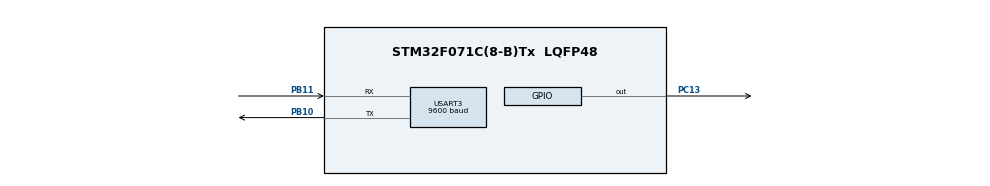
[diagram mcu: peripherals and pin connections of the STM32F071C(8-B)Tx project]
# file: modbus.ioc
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Mcu.Family=STM32F0
Mcu.Name=STM32F071C(8-B)Tx
Mcu.Package=LQFP48
NVIC.USART3_4_IRQn=true\:0\:0\:false\:false\:true\:true\:true\:true
PB10.Mode=Asynchronous
PB10.Signal=USART3_TX
PB11.Mode=Asynchronous
PB11.Signal=USART3_RX
PC13.Signal=GPIO_Output
ProjectManager.HeapSize=0x200
ProjectManager.StackSize=0x400
ProjectManager.TargetToolchain=STM32CubeIDE
USART3.BaudRate=9600
USART3.VirtualMode-Asynchronous=VM_ASYNC
board=custom

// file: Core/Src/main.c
/* USER CODE BEGIN Header */
/**
  ******************************************************************************
  * @file           : main.c
  * @brief          : Main program body
  ******************************************************************************
  * @attention
  *
  * Copyright (c) 2025 STMicroelectronics.
  * All rights reserved.
  *
  * This software is licensed under terms that can be found in the LICENSE file
  * in the root directory of this software component.
  * If no LICENSE file comes with this software, it is provided AS-IS.
  *
  ******************************************************************************
  */
/* USER CODE END Header */
#include "main.h"

/* USER CODE BEGIN Includes */
#include <string.h>
#include <stdio.h>
/* USER CODE END Includes */

UART_HandleTypeDef huart3;

/* USER CODE BEGIN PV */

uint16_t ModBus_CRC16(uint8_t *data, uint16_t length) {
  uint16_t crc = 0xFFFF;    // Initial value
  uint16_t i, j;

  for(i = 0; i < length; i++) {
      crc ^= data[i];       // XOR byte with CRC
      for(j = 0; j < 8; j++) {   // Process each bit
          if(crc & 0x0001) {     // If LSB is 1
              crc = (crc >> 1) ^ 0xA001;  // Shift right and XOR with polynomial
          } else {
              crc = crc >> 1;    // Just shift right
          }
      }
  }

  return crc;
}

/* USER CODE END PV */

void SystemClock_Config(void);
static void MX_GPIO_Init(void);
static void MX_USART3_UART_Init(void);

int main(void)
{

  /* MCU Configuration--------------------------------------------------------*/

  /* Reset of all peripherals, Initializes the Flash interface and the Systick. */
  HAL_Init();

  /* Configure the system clock */
  SystemClock_Config();

  /* Initialize all configured peripherals */
  MX_GPIO_Init();
  MX_USART3_UART_Init();
  /* USER CODE BEGIN 2 */
  uint8_t buffer[256];

  sprintf((char *)buffer, "Hello, World!\n");
  HAL_UART_Transmit(&huart3, buffer, strlen((char *)buffer), 100);
  int count = 0;
  uint8_t test = 0x00;
  uint8_t* arr_test = &test;
  uint8_t data;
  /* USER CODE END 2 */

  /* Infinite loop */
  while (1)
  {
    HAL_UART_Receive(&huart3, &data, sizeof(data),10);
    // if(data == 'a')
    {
      HAL_UART_Transmit(&huart3, "hi\r\n", 4, 100);

      HAL_Delay(1000);

      uint8_t response[] = {0x01, 0x03, 0x02, 0x11, *arr_test, 0xB4, 0x27};
      uint16_t crc = ModBus_CRC16(response, sizeof(response) - 2);
      uint8_t crc_low = crc & 0xFF;
      uint8_t crc_high = (crc >> 8) & 0xFF;
      response[sizeof(response) - 2] = crc_low;
      response[sizeof(response) - 1] = crc_high;

	    HAL_UART_Transmit(&huart3, &response, sizeof(response), 100);
	    HAL_Delay(1000);
      test++;
    }
	  HAL_Delay(1000);
  }
}

void SystemClock_Config(void)
{
  RCC_OscInitTypeDef RCC_OscInitStruct = {0};
  RCC_ClkInitTypeDef RCC_ClkInitStruct = {0};

  /** Initializes the RCC Oscillators according to the specified parameters
  * in the RCC_OscInitTypeDef structure.
  */
  RCC_OscInitStruct.OscillatorType = RCC_OSCILLATORTYPE_HSI;
  RCC_OscInitStruct.HSIState = RCC_HSI_ON;
  RCC_OscInitStruct.HSICalibrationValue = RCC_HSICALIBRATION_DEFAULT;
  RCC_OscInitStruct.PLL.PLLState = RCC_PLL_NONE;
  if (HAL_RCC_OscConfig(&RCC_OscInitStruct) != HAL_OK)
  {
    Error_Handler();
  }

  /** Initializes the CPU, AHB and APB buses clocks
  */
  RCC_ClkInitStruct.ClockType = RCC_CLOCKTYPE_HCLK|RCC_CLOCKTYPE_SYSCLK
                              |RCC_CLOCKTYPE_PCLK1;
  RCC_ClkInitStruct.SYSCLKSource = RCC_SYSCLKSOURCE_HSI;
  RCC_ClkInitStruct.AHBCLKDivider = RCC_SYSCLK_DIV1;
  RCC_ClkInitStruct.APB1CLKDivider = RCC_HCLK_DIV1;

  if (HAL_RCC_ClockConfig(&RCC_ClkInitStruct, FLASH_LATENCY_0) != HAL_OK)
  {
    Error_Handler();
  }
}

static void MX_USART3_UART_Init(void)
{

  huart3.Instance = USART3;
  huart3.Init.BaudRate = 9600;
  huart3.Init.WordLength = UART_WORDLENGTH_8B;
  huart3.Init.StopBits = UART_STOPBITS_1;
  huart3.Init.Parity = UART_PARITY_NONE;
  huart3.Init.Mode = UART_MODE_TX_RX;
  huart3.Init.HwFlowCtl = UART_HWCONTROL_NONE;
  huart3.Init.OverSampling = UART_OVERSAMPLING_16;
  huart3.Init.OneBitSampling = UART_ONE_BIT_SAMPLE_DISABLE;
  huart3.AdvancedInit.AdvFeatureInit = UART_ADVFEATURE_NO_INIT;
  if (HAL_UART_Init(&huart3) != HAL_OK)
  {
    Error_Handler();
  }

}

static void MX_GPIO_Init(void)
{
  GPIO_InitTypeDef GPIO_InitStruct = {0};

  /* GPIO Ports Clock Enable */
  __HAL_RCC_GPIOC_CLK_ENABLE();
  __HAL_RCC_GPIOB_CLK_ENABLE();

  /*Configure GPIO pin Output Level */
  HAL_GPIO_WritePin(GPIOC, GPIO_PIN_13, GPIO_PIN_RESET);

  /*Configure GPIO pin : PC13 */
  GPIO_InitStruct.Pin = GPIO_PIN_13;
  GPIO_InitStruct.Mode = GPIO_MODE_OUTPUT_PP;
  GPIO_InitStruct.Pull = GPIO_NOPULL;
  GPIO_InitStruct.Speed = GPIO_SPEED_FREQ_LOW;
  HAL_GPIO_Init(GPIOC, &GPIO_InitStruct);

}

void Error_Handler(void)
{
  __disable_irq();
  while (1)
  {
  }
}
